# CH32V407 register map
Vendor: WCH Ltd.; File version: 1.0
Registers are 32-bit, read-write, reset 0x0 unless marked. A register's access mark holds for its fields unless they carry their own. Offsets are from the block's base; [hi:lo] are bit positions.

## FSMC — Flexible static memory controller
Base 0xA0000000
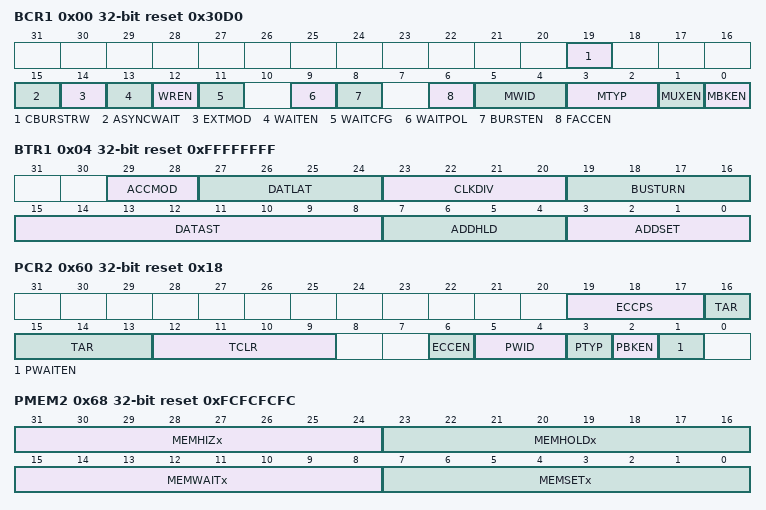
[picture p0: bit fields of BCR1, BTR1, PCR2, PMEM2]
0x00 BCR1 reset 0x30D0 — SRAM/NOR-Flash chip-select control register 1
  [19] CBURSTRW — Write burst enable
  [15] ASYNCWAIT — Wait signal during asynchronous transfers
  [14] EXTMOD — Extended mode enable
  [13] WAITEN — Wait enable bit
  [12] WREN — Write enable bit
  [11] WAITCFG — Wait timing configuration
  [9] WAITPOL — Wait signal polarity bit
  [8] BURSTEN — Burst enable bit
  [6] FACCEN — Flash access enable
  [5:4] MWID — Memory databus width
  [3:2] MTYP — Memory type
  [1] MUXEN — Address/data multiplexing enable bit
  [0] MBKEN — Memory bank enable bit
0x04 BTR1 reset 0xFFFFFFFF — SRAM/NOR-Flash chip-select timing register 1
  [29:28] ACCMOD — Access mode
  [27:24] DATLAT — Data latency for synchronous NOR Flash memory
  [23:20] CLKDIV — Clock divide ratio (for FSMC_CLK signal)
  [19:16] BUSTURN — Bus turnaround phase duration
  [15:8] DATAST — Data-phase duration
  [7:4] ADDHLD — Address-hold phase duration
  [3:0] ADDSET — Address setup phase duration
0x60 PCR2 reset 0x18 — PC Card/NAND Flash control register 2
  [19:17] ECCPS — ECC page size
  [16:13] TAR — ALE to RE delay
  [12:9] TCLR — CLE to RE delay
  [6] ECCEN — ECC computation logic enable bit
  [5:4] PWID — Databus width
  [3] PTYP — Memory type
  [2] PBKEN — PC Card/NAND Flash memory bank enable bit
  [1] PWAITEN — Wait feature enable bit
0x64 SR2 ro reset 0x40 — FIFO status and interrupt register 2
  [6] FEMPT — FIFO empty
0x68 PMEM2 reset 0xFCFCFCFC — Common memory space timing register 2
  [31:24] MEMHIZx — Common memory x databus HiZ time
  [23:16] MEMHOLDx — Common memory x hold time
  [15:8] MEMWAITx — Common memory x wait time
  [7:0] MEMSETx — Common memory x setup time
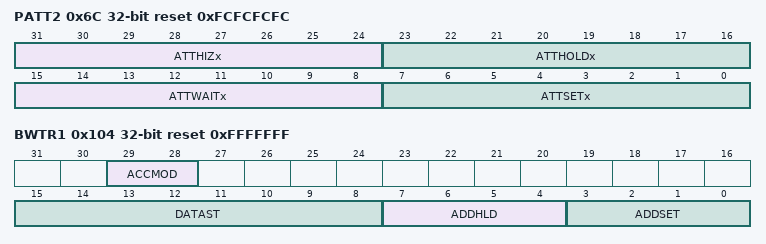
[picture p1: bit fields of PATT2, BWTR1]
0x6C PATT2 reset 0xFCFCFCFC — Attribute memory space timing register 2
  [31:24] ATTHIZx — Attribute memory x databus HiZ time
  [23:16] ATTHOLDx — Attribute memory x hold time
  [15:8] ATTWAITx — Attribute memory x wait time
  [7:0] ATTSETx — Attribute memory x setup time
0x74 ECCR2 ro — ECC result register 2
  [31:0] ECCx — ECC result
0x104 BWTR1 reset 0xFFFFFFF — SRAM/NOR-Flash write timing registers 1
  [29:28] ACCMOD — Access mode
  [15:8] DATAST — Data-phase duration
  [7:4] ADDHLD — Address-hold phase duration
  [3:0] ADDSET — Address setup phase duration

## ESIG — ESIG configuration
Base 0x1FFFF7E0
0x00 FLACAP 16-bit ro — Flash capecity register
  [15:0] F_SIZE — F_SIZE/kByte
0x08 UNIID1 ro — UID register
  [31:0] U_ID — U_ID value
0x0C UNIID2 ro — UID register
  [31:0] U_ID — U_ID value
0x10 UNIID3 ro — Div register
  [31:0] U_ID — U_ID value

## FLASH
Base 0x40022000
0x04 KEYR wo — Flash key register
  [31:0] KEYR — FPEC key
0x08 OBKEYR wo — Flash option key register
  [31:0] OBTKEY — Option byte key
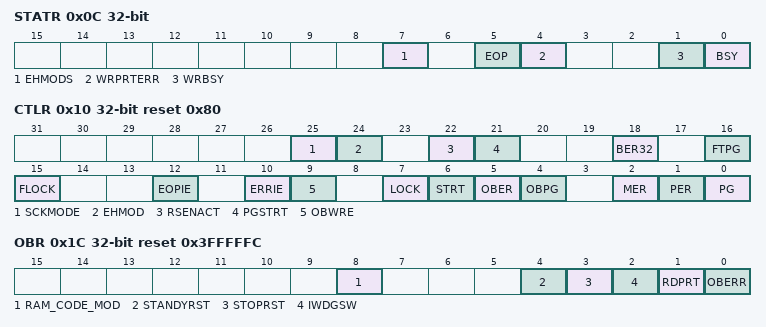
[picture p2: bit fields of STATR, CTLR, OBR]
0x0C STATR access per field — Status register
  [7] EHMODS ro — Enhance mode start
  [5] EOP rw — End of operation
  [4] WRPRTERR rw — Write protection error
  [1] WRBSY ro — Quick page programming
  [0] BSY ro — Busy
0x10 CTLR reset 0x80 — Control register
  [25] SCKMODE — Flash SCK mode
  [24] EHMOD — Flash Enhance read mode
  [22] RSENACT — Reset Flash Enhance read mode
  [21] PGSTRT — Page Programming Start
  [18] BER32 — Block Erase 32K
  [16] FTPG — Fast programming
  [15] FLOCK — Fast programmable lock
  [12] EOPIE — End of operation interrupt enable
  [10] ERRIE — Error interrupt enable
  [9] OBWRE — Option bytes write enable
  [7] LOCK
  [6] STRT — Start
  [5] OBER — Option byte erase
  [4] OBPG — Option byte programming
  [2] MER — Mass Erase
  [1] PER — Page Erase
  [0] PG — Programming
0x14 ADDR wo — Flash address register
  [31:0] FAR — Flash Address
0x1C OBR ro reset 0x3FFFFFC — Option byte register
  [8] RAM_CODE_MOD
  [4] STANDYRST
  [3] STOPRST
  [2] IWDGSW
  [1] RDPRT — Read protection
  [0] OBERR — Option byte error
0x20 WPR ro reset 0xFFFFFFFF — Write protection register
  [31:0] WRP — Write protect
0x24 MODEKEYR wo — Mode select register
  [31:0] MODEKEYR — Mode select
